AUTOSAR XML (schema 00051)
package /Components
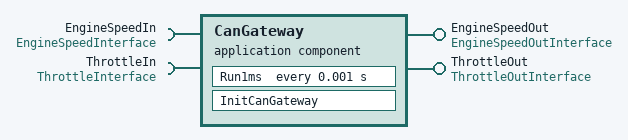
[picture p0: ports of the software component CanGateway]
  application sw component type CanGateway
    require port EngineSpeedIn: required-interface=EngineSpeedInterface
    require port ThrottleIn: required-interface=ThrottleInterface
    provide port EngineSpeedOut: provided-interface=EngineSpeedOutInterface
    provide port ThrottleOut: provided-interface=ThrottleOutInterface
    behavior CanGateway_IB
      timing event TE_Run1ms: start-on-event=Run1ms, period=0.001
      init event IE_InitCanGateway: start-on-event=InitCanGateway
      runnable Run1ms
        data-read-access:
          access VA_Run1ms_EngineSpeedIn: accessed-variable=EngineSpeedIn.EngineSpeed
          access VA_Run1ms_ThrottleIn: accessed-variable=ThrottleIn.ThrottlePosition
        data-write-access:
          access VA_Run1ms_EngineSpeedOut: accessed-variable=EngineSpeedOut.EngineSpeedFwd
          access VA_Run1ms_ThrottleOut: accessed-variable=ThrottleOut.ThrottlePositionFwd
      runnable InitCanGateway
